# ESP32S31_RADIO register map
Vendor: Espressif; Series: ESP32-S31; File version: 3.52
Registers are 32-bit, read-write, no defined reset value unless marked. A register's access mark holds for its fields unless they carry their own. Offsets are from the block's base; [hi:lo] are bit positions; 'fields as' and 'values as' point back to an identical list.

## PHY_FECOEX_RECOVERED — Sparse FECOEX words absent from the public platform PAC.
Base 0x20100000
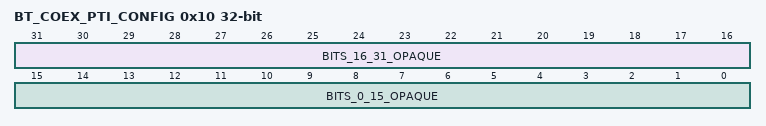
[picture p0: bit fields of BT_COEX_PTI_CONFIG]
0x10 BT_COEX_PTI_CONFIG — Project-assigned name. Complete coex_pti_v2 performs two ordered fresh-read RMW operations: it first replaces bits 31:16 with 0x0640, then replaces bits 15:0 with 0x0010. Individual bit meanings remain unknown.
  [31:16] BITS_16_31_OPAQUE — Opaque: meaning not established. Fixed 0x0640 image published by the first coex_pti_v2 RMW.
    on write: 0x640=REVIEWED_IMAGE (The only high-halfword image proved by coex_pti_v2.)
  [15:0] BITS_0_15_OPAQUE — Opaque: meaning not established. Fixed 0x0010 image published by the second coex_pti_v2 RMW.
    on write: 16=REVIEWED_IMAGE (The only low-halfword image proved by coex_pti_v2.)

## PHY_FEDATA_RECOVERED — Sparse FEDATA words absent from the public platform PAC.
Base 0x20100400
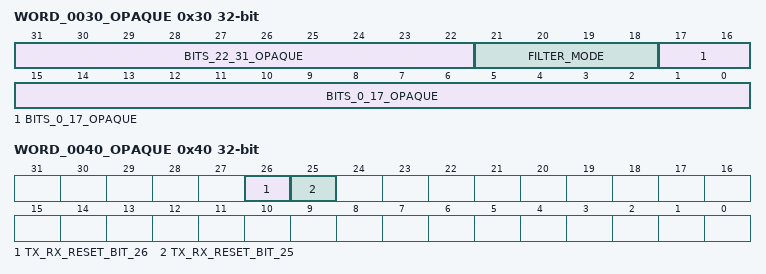
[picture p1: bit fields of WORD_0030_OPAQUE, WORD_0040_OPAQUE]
0x30 WORD_0030_OPAQUE — Opaque: meaning not established. Complete phy_rx_filter_mode performs a read-modify-write of FILTER_MODE; the other fields remain unnamed.
  [31:22] BITS_22_31_OPAQUE — Opaque: meaning not established. Observed source use; the individual hardware meaning is unknown.
  [21:18] FILTER_MODE — Project-assigned name. Receive filter mode: complete phy_rx_filter_mode replaces these bits with the low four bits of its argument and preserves every other bit.
  [17:0] BITS_0_17_OPAQUE — Opaque: meaning not established. Observed source use; the individual hardware meaning is unknown.
0x40 WORD_0040_OPAQUE — Opaque: meaning not established. Complete phy_fe_txrx_reset clears then asserts bits 25 and 26 through two fresh-read RMWs. Bits 12:24 are preserved by both edges and have no field. SOURCE: ROM_REV0_PHY_BLOBRAY_GAPS.
  [26] TX_RX_RESET_BIT_26 — Project-assigned name. Second upper reset bit cleared and then asserted by complete phy_fe_txrx_reset.
  [25] TX_RX_RESET_BIT_25 — Project-assigned name. First upper reset bit asserted by complete phy_fe_txrx_reset.

## PHY_FECTRL_RECOVERED — Sparse FECTRL antenna words absent from the public platform PAC.
Base 0x20100800
0x34 WORD_0034_OPAQUE — Opaque: meaning not established. Read-modify-written by complete antenna configuration functions and saved/restored by complete phy_dig_reg_backup.
  [31:0] BITS_0_31_OPAQUE — Opaque: meaning not established. Observed source use; the individual hardware meaning is unknown.
0x38 WORD_0038_OPAQUE — Opaque: meaning not established. Read-modify-written by complete antenna configuration functions and saved/restored by complete phy_dig_reg_backup.
  fields as WORD_0034_OPAQUE
0x3C WORD_003C_OPAQUE — Opaque: meaning not established. Read-modify-written by complete antenna configuration functions and saved/restored by complete phy_dig_reg_backup.
  fields as WORD_0034_OPAQUE
0x40 WORD_0040_OPAQUE — Opaque: meaning not established. Read-modify-written by complete antenna configuration functions and saved/restored by complete phy_dig_reg_backup.
  fields as WORD_0034_OPAQUE

## PHY_FEDATA_WIFI_RECOVERED — Sparse FEDATA_WIFI words absent from the public platform PAC.
Base 0x20100C00
0x14 WORD_0014_OPAQUE — Opaque: meaning not established. Complete phy_bb_cfo_cfg reads and replaces this word; individual hardware fields remain unnamed.
  [30:19] BITS_19_30_OPAQUE — Opaque: meaning not established. Observed source use; the individual hardware meaning is unknown.
0x18 WORD_0018_OPAQUE — Opaque: meaning not established. Complete phy_freq_correct read-modify-writes this word; individual fields remain unnamed.
  [31:0] BITS_0_31_OPAQUE — Opaque: meaning not established. Observed source use; the individual hardware meaning is unknown.
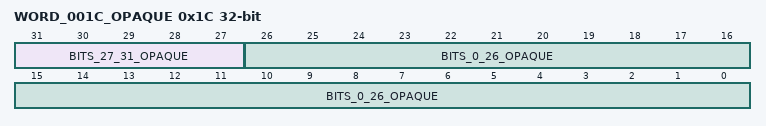
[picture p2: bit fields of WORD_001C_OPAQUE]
0x1C WORD_001C_OPAQUE — Opaque: meaning not established. Complete phy_freq_correct read-modify-writes this word; individual fields remain unnamed.
  [31:27] BITS_27_31_OPAQUE — Opaque: meaning not established. Observed source use; the individual hardware meaning is unknown.
  [26:0] BITS_0_26_OPAQUE — Opaque: meaning not established. Observed source use; the individual hardware meaning is unknown.
